# RT584ZCM33 register map
Series: ARMv8-M Mainline; File version: 1.0
CPU: CM33 r0p0, little endian, MPU, no FPU, VTOR, 3 interrupt priority bits
Registers are 32-bit, read-write, reset 0x0 unless marked. A register's access mark holds for its fields unless they carry their own. Offsets are from the block's base; [hi:lo] are bit positions; 'fields as' and 'values as' point back to an identical list.

## RTC_Non-Secure — RTC Non-Secure Register block
Base 0x40004000
Same registers: RTC_Secure 0x50004000
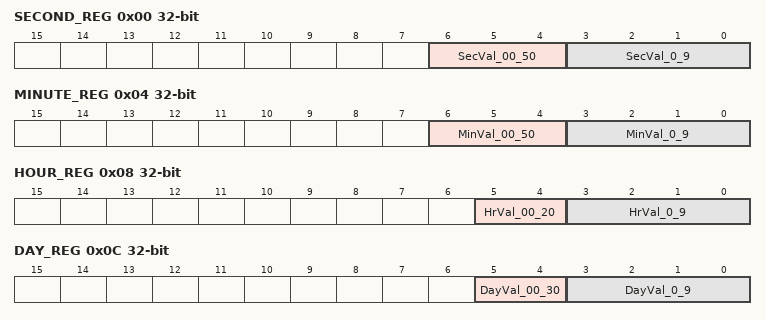
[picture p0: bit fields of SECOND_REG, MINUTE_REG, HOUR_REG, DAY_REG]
0x00 SECOND_REG — second
  [6:4] SecVal_00_50 — The RTC Timer second setting value tens digits in BCD format
    0=B_4_to_6 (The RTC Timer second setting value tens digits in BCD format)
  [3:0] SecVal_0_9 — The RTC Timer second setting value digits in BCD format
    0=B_0_to_3 (The RTC Timer second setting value digits in BCD format)
0x04 MINUTE_REG — minute
  [6:4] MinVal_00_50 — The RTC Timer minute setting value tens digits in BCD format
    0=B_4_to_6 (The RTC Timer minute setting value tens digits in BCD format)
  [3:0] MinVal_0_9 — The RTC Timer minute setting value digits in BCD format
    0=B_0_to_3 (The RTC Timer minute setting value digits in BCD format)
0x08 HOUR_REG — hour
  [5:4] HrVal_00_20 — The RTC Timer hour setting value tens digits in BCD format
    0=B_4_to_5 (The RTC Timer hour setting value tens digits in BCD format)
  [3:0] HrVal_0_9 — The RTC Timer hour setting value digits in BCD format
    0=B_0_to_3 (The RTC Timer hour setting value digits in BCD format)
0x0C DAY_REG — day
  [5:4] DayVal_00_30 — The RTC Timer day setting value tens digits in BCD format
    0=B_4_to_5 (The RTC Timer day setting value tens digits in BCD format)
  [3:0] DayVal_0_9 — The RTC Timer day setting value digits in BCD format
    0=B_0_to_3 (The RTC Timer day setting value digits in BCD format)
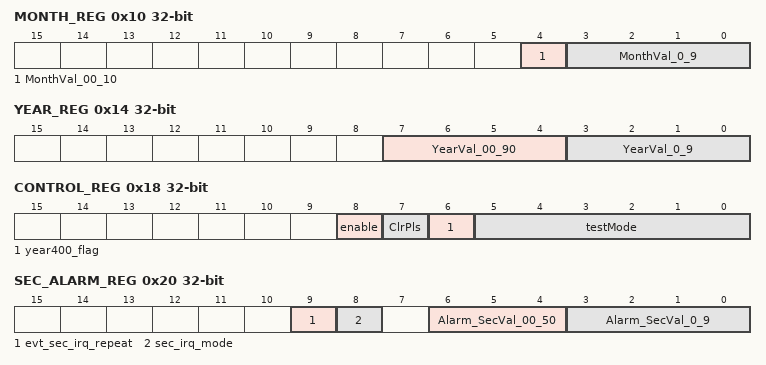
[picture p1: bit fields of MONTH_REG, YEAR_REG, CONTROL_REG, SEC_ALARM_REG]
0x10 MONTH_REG — month
  [4] MonthVal_00_10 — The RTC Timer month setting value tens digits in BCD format
    0=B_4 (The RTC Timer month setting value tens digits in BCD format)
  [3:0] MonthVal_0_9 — The RTC Timer month setting value digits in BCD format
    0=B_0_to_3 (The RTC Timer month setting value digits in BCD format)
0x14 YEAR_REG — year
  [7:4] YearVal_00_90 — The RTC Timer month setting value tens digits in BCD format
    0=B_4_to_7 (The RTC Timer month setting value tens digits in BCD format)
  [3:0] YearVal_0_9 — The RTC Timer month setting value digits in BCD format
    values as MONTH_REG.MonthVal_0_9
0x18 CONTROL_REG — control
  [8] enable — RTC timer counter enable control 0: disable 1: enable
    0=B_8_ITEM0 (disable); 1=B_8_ITEM1 (enable)
  [7] ClrPls — When 1 is written, creates a pulse on the clk32k domain to clear all counters and values there to their initial state. A write of 0 to this bit has no effect. Read: 1=Clear in progress, 0=Clear done.
    0=B_7 (When 1 is written, creates a pulse on the clk32k domain to clear all counters and values there to their initial state. A write of 0 to this bit has no effect. Read: 1=Clear in progress, 0=Clear done.)
  [6] year400_flag — If year div 400=0, this flag set to 1
    0=B_6 (If year div 400=0, this flag set to 1)
  [5:0] testMode — Used to speed up Time Unit counters for test. If a bit is set to 1, then the corresponding time unit counter will change on the same timing as Seconds. [0]=Unused, [1]=Minutes, [2]=Hours, [3]=Days, [4]=Months, [5]=Years.
    0=B_0_to_5 (Used to speed up Time Unit counters for test. If a bit is set to 1, then the corresponding time unit counter will change on the same timing as Seconds. [0]=Unused, [1]=Minutes, [2]=Hours, [3]=Days, [4]=Months, [5]=Years.)
0x1C CLK_DIV_REG reset 0x200000 — clk div
  [23:0] ms_DivVal — milli Sec Divided setting value of clk32K. Setting to generate 1 ms Clk. ms_DivVal[23:16] is integer part and can't be 0, ms_DivVal[15:0] is frational part Ex. 32.768K, 32.768=0x20.c49c, ms_DivVal=20c49c
0x20 SEC_ALARM_REG — sec alarm
  [9] evt_sec_irq_repeat — if set to 1, event irq trigger at every second
    0=B_9 (if set to 1, event irq trigger at every second)
  [8] sec_irq_mode — sec irq mode setting value 0: irq at alarm second 1: irq at every second
    0=B_8_ITEM0 (irq at alarm second); 1=B_8_ITEM1 (irq at every second)
  [6:4] Alarm_SecVal_00_50 — Second Timer alarm setting value tens digits in BCD format
    0=B_4_to_6 (Second Timer alarm setting value tens digits in BCD format)
  [3:0] Alarm_SecVal_0_9 — Second Timer alarm setting value digits in BCD format
    0=B_0_to_3 (Second Timer alarm setting value digits in BCD format)
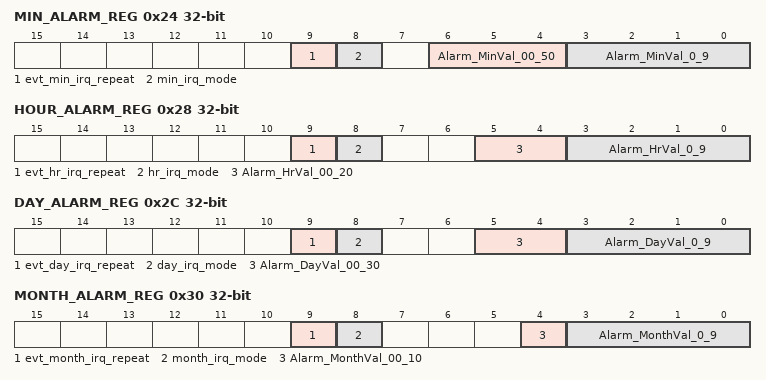
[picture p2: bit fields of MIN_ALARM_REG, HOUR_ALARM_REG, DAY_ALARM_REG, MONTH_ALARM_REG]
0x24 MIN_ALARM_REG — min alarm
  [9] evt_min_irq_repeat — Note: This field is relevant only when evt_sec_irq_repeat is not set if set to 1, event irq trigger at every second alarm match
    0=B_9 (Note: This field is relevant only when evt_sec_irq_repeat is not set if set to 1, event irq trigger at every second alarm match)
  [8] min_irq_mode — min irq mode setting value 0: irq at alarm minute 1: irq at every minute
    0=B_8_ITEM0 (irq at alarm minute); 1=B_8_ITEM1 (irq at every minute)
  [6:4] Alarm_MinVal_00_50 — Minute Timer alarm setting value tens digits in BCD format
    0=B_4_to_6 (Minute Timer alarm setting value tens digits in BCD format)
  [3:0] Alarm_MinVal_0_9 — Minute Timer alarm setting value digits in BCD format
    0=B_0_to_3 (Minute Timer alarm setting value digits in BCD format)
0x28 HOUR_ALARM_REG — hour alarm
  [9] evt_hr_irq_repeat — Note: This field is relevant only when evt_sec_irq_repeat and evt_min_irq_repeat is not set if set to 1, event irq trigger at every second alarm match and minute alarm match
    0=B_9 (Note: This field is relevant only when evt_sec_irq_repeat and evt_min_irq_repeat is not set if set to 1, event irq trigger at every second alarm match and minute alarm match)
  [8] hr_irq_mode — hour irq mode setting value 0: irq at alarm hour 1: irq at every hour
    0=B_8_ITEM0 (irq at alarm hour); 1=B_8_ITEM1 (irq at every hour)
  [5:4] Alarm_HrVal_00_20 — Hour Timer alarm setting value tens digits in BCD format
    0=B_4_to_5 (Hour Timer alarm setting value tens digits in BCD format)
  [3:0] Alarm_HrVal_0_9 — Hour Timer alarm setting value digits in BCD format
    0=B_0_to_3 (Hour Timer alarm setting value digits in BCD format)
0x2C DAY_ALARM_REG — day alarm
  [9] evt_day_irq_repeat — Note: This field is relevant only when evt_sec_irq_repeat, evt_min_irq_repeat and evt_hr_irq_repeat is not set if set to 1, event irq trigger at every second alarm match, minute alarm match, and hour alarm match
    0=B_9 (Note: This field is relevant only when evt_sec_irq_repeat, evt_min_irq_repeat and evt_hr_irq_repeat is not set if set to 1, event irq trigger at every second alarm match, minute alarm match, and hour alarm match)
  [8] day_irq_mode — day irq mode setting value 0: irq at alarm day 1: irq at every day
    0=B_8_ITEM0 (irq at alarm day); 1=B_8_ITEM1 (irq at every day)
  [5:4] Alarm_DayVal_00_30 — Day Timer alarm setting value tens digits in BCD format
    0=B_4_to_5 (Day Timer alarm setting value tens digits in BCD format)
  [3:0] Alarm_DayVal_0_9 — Day Timer alarm setting value digits in BCD format
    0=B_0_to_3 (Day Timer alarm setting value digits in BCD format)
0x30 MONTH_ALARM_REG — month alarm
  [9] evt_month_irq_repeat — Note: This field is relevant only when evt_sec_irq_repeat, evt_min_irq_repeat ,evt_hr_irq_repeat and evt_day_irq_repeat is not set if set to 1, event irq trigger at every second alarm match, minute alarm match, hour alarm match, and day alarm match
    0=B_9 (Note: This field is relevant only when evt_sec_irq_repeat, evt_min_irq_repeat ,evt_hr_irq_repeat and evt_day_irq_repeat is not set if set to 1, event irq trigger at every second alarm match, minute alarm match, hour alarm match, and day alarm match)
  [8] month_irq_mode — month irq mode setting value 0: irq at alarm month 1: irq at every month
    0=B_8_ITEM0 (irq at alarm month); 1=B_8_ITEM1 (irq at every month)
  [4] Alarm_MonthVal_00_10 — Month Timer alarm setting value tens digits in BCD format
    0=B_4 (Month Timer alarm setting value tens digits in BCD format)
  [3:0] Alarm_MonthVal_0_9 — Month Timer alarm setting value digits in BCD format
    0=B_0_to_3 (Month Timer alarm setting value digits in BCD format)
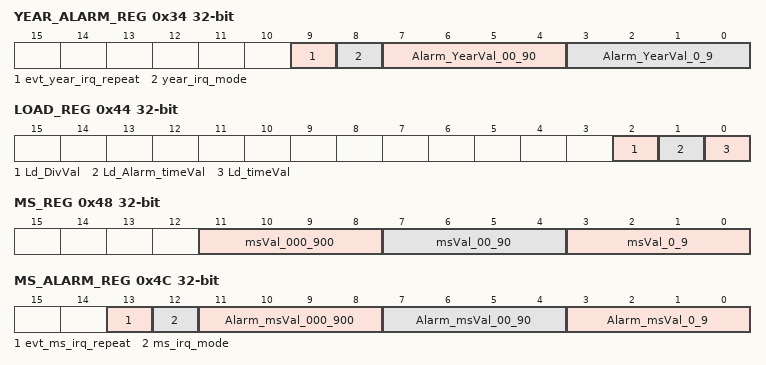
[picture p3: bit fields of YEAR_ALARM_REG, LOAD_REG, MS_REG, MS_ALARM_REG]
0x34 YEAR_ALARM_REG — year alarm
  [9] evt_year_irq_repeat — Note: This field is relevant only when evt_sec_irq_repeat, evt_min_irq_repeat ,evt_hr_irq_repeat, evt_day_irq_repeat and evt_month_irq_repeat is not set if set to 1, event irq trigger at every second alarm match, minute alarm match, hour alarm match, day alarm match, and month alarm match
    0=B_9 (Note: This field is relevant only when evt_sec_irq_repeat, evt_min_irq_repeat ,evt_hr_irq_repeat, evt_day_irq_repeat and evt_month_irq_repeat is not set if set to 1, event irq trigger at every second alarm match, minute alarm match, hour alarm match, day alarm match, and month alarm match)
  [8] year_irq_mode — year irq mode setting value 0: irq at alarm year 1: irq at every year
    0=B_8_ITEM0 (irq at alarm year); 1=B_8_ITEM1 (irq at every year)
  [7:4] Alarm_YearVal_00_90 — Year Timer alarm value tens digits in BCD format
    0=B_4_to_7 (Year Timer alarm value tens digits in BCD format)
  [3:0] Alarm_YearVal_0_9 — Year Timer alarm value digits in BCD format
    0=B_0_to_3 (Year Timer alarm value digits in BCD format)
0x38 INT_CONTROL_REG — int control
  [7:0] int_en — RTC timer interrupt enable int_en[0]=sec alarm irq enable int_en[1]=min alarm irq enable int_en[2]=hour alarm irq enable int_en[3]=day alarm irq enable int_en[4]=month alarm irq enable int_en[5]=year alarm irq enable int_en[6]=event alarm irq enable int_en[7]=ms alarm irq enable
    0=B_0_to_7 (RTC timer interrupt enable int_en[0]=sec alarm irq enable int_en[1]=min alarm irq enable int_en[2]=hour alarm irq enable int_en[3]=day alarm irq enable int_en[4]=month alarm irq enable int_en[5]=year alarm irq enable int_en[6]=event alarm irq enable int_en[7]=ms alarm irq enable)
0x3C INT_STATUS_REG ro — int status
  [7:0] int_st — RTC timer interrupt status int_en[0]=sec alarm irq status int_en[1]=min alarm irq status int_en[2]=hour alarm irq status int_en[3]=day alarm irq status int_en[4]=month alarm irq status int_en[5]=year alarm irq status int_en[6]=event alarm irq status int_en[7]=ms alarm irq status
    0=B_0_to_7 (RTC timer interrupt status int_en[0]=sec alarm irq status int_en[1]=min alarm irq status int_en[2]=hour alarm irq status int_en[3]=day alarm irq status int_en[4]=month alarm irq status int_en[5]=year alarm irq status int_en[6]=event alarm irq status int_en[7]=ms alarm irq status)
0x40 INT_CLEAR_REG wo — int clear
  [7:0] int_clr — RTC timer interrupt clear int_clr[0]=sec alarm irq clear int_clr[1]=min alarm irq clear int_clr[2]=hour alarm irq clear int_clr[3]=day alarm irq clear int_clr[4]=month alarm irq clear int_clr[5]=year alarm irq clear int_clr[6]=event alarm irq clear int_clr[7]=ms alarm irq clear
    0=B_0_to_7 (RTC timer interrupt clear int_clr[0]=sec alarm irq clear int_clr[1]=min alarm irq clear int_clr[2]=hour alarm irq clear int_clr[3]=day alarm irq clear int_clr[4]=month alarm irq clear int_clr[5]=year alarm irq clear int_clr[6]=event alarm irq clear int_clr[7]=ms alarm irq clear)
0x44 LOAD_REG — load
  [2] Ld_DivVal — Write 1 to load clk diveded value to 32K clk domain. If read=1, load in progress, if read=0, load done.
    0=B_2 (Write 1 to load clk diveded value to 32K clk domain. If read=1, load in progress, if read=0, load done.)
  [1] Ld_Alarm_timeVal — Write 1 to load alarm time value to 32K clk domain. If read=1, load in progress, if read=0, load done.
    0=B_1 (Write 1 to load alarm time value to 32K clk domain. If read=1, load in progress, if read=0, load done.)
  [0] Ld_timeVal — Write 1 to load time value to 32K clk domain. If read=1, load in progress, if read=0, load done.
    0=B_0 (Write 1 to load time value to 32K clk domain. If read=1, load in progress, if read=0, load done.)
0x48 MS_REG — ms
  [11:8] msVal_000_900 — The RTC Timer milli second setting value hundreds digits in BCD format
    0=B_8_to_11 (The RTC Timer milli second setting value hundreds digits in BCD format)
  [7:4] msVal_00_90 — The RTC Timer milli second setting value tens digits in BCD format
    0=B_4_to_7 (The RTC Timer milli second setting value tens digits in BCD format)
  [3:0] msVal_0_9 — The RTC Timer milli second setting value digits in BCD format
    0=B_0_to_3 (The RTC Timer milli second setting value digits in BCD format)
0x4C MS_ALARM_REG — ms alarm
  [13] evt_ms_irq_repeat — if set to 1, event irq trigger at every milli second
    0=B_13 (if set to 1, event irq trigger at every milli second)
  [12] ms_irq_mode — ms irq mode setting value 0: irq at alarm milli second 1: irq at every milli second
    0=B_12_ITEM0 (irq at alarm milli second); 1=B_12_ITEM1 (irq at every milli second)
  [11:8] Alarm_msVal_000_900 — ms Timer alarm setting value hundreds digits in BCD format
    0=B_8_to_11 (ms Timer alarm setting value hundreds digits in BCD format)
  [7:4] Alarm_msVal_00_90 — ms Timer alarm setting value tens digits in BCD format
    0=B_4_to_7 (ms Timer alarm setting value tens digits in BCD format)
  [3:0] Alarm_msVal_0_9 — ms Timer alarm setting value digits in BCD format
    0=B_0_to_3 (ms Timer alarm setting value digits in BCD format)
